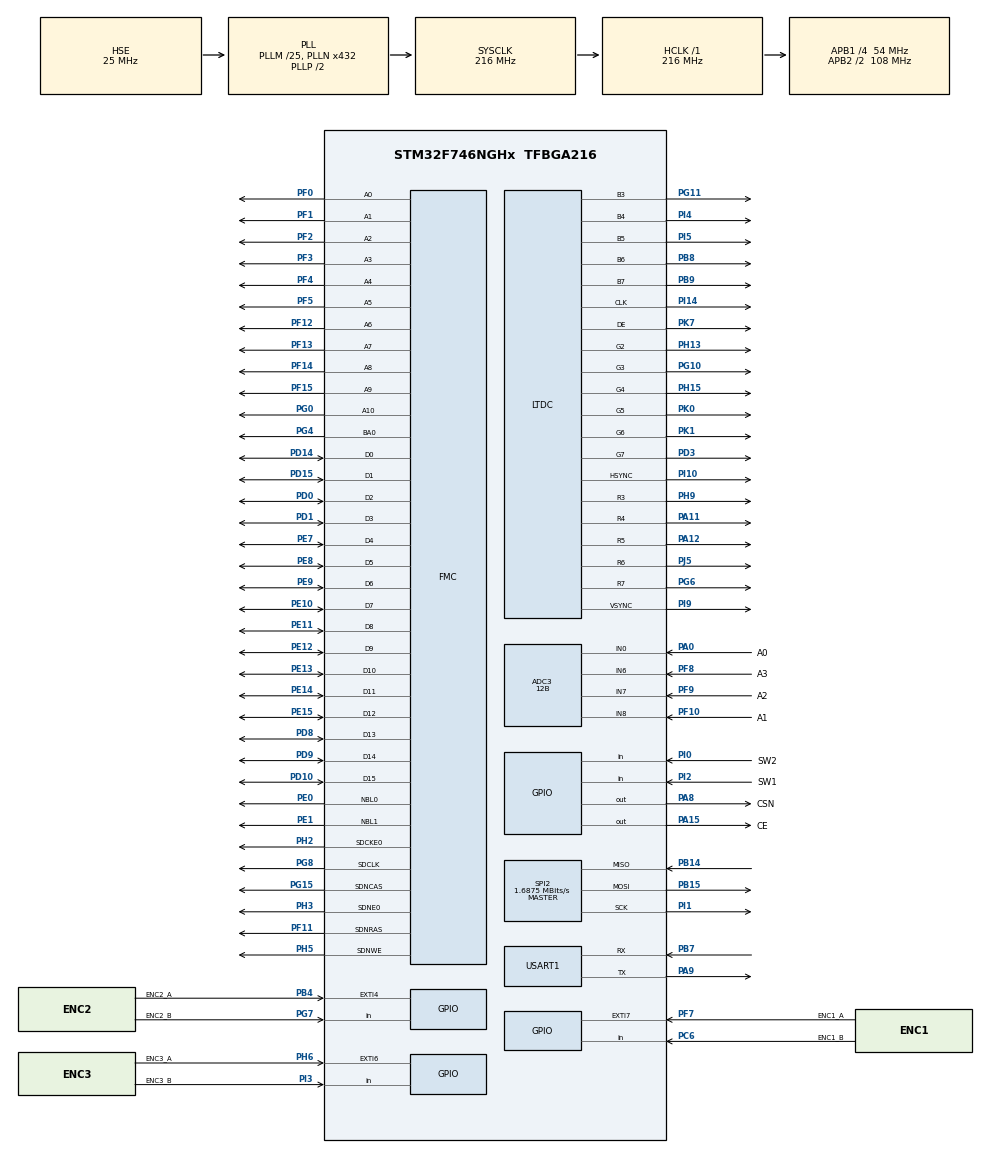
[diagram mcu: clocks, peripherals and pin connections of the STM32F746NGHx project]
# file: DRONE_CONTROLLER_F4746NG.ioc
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ADC3.Channel-0\#ChannelRegularConversion=ADC_CHANNEL_0
ADC3.Channel-1\#ChannelRegularConversion=ADC_CHANNEL_6
ADC3.Channel-2\#ChannelRegularConversion=ADC_CHANNEL_7
ADC3.Channel-3\#ChannelRegularConversion=ADC_CHANNEL_8
ADC3.ClockPrescaler=ADC_CLOCK_SYNC_PCLK_DIV4
ADC3.ContinuousConvMode=DISABLE
ADC3.DMAContinuousRequests=ENABLE
ADC3.EOCSelection=ADC_EOC_SEQ_CONV
ADC3.ExternalTrigConv=ADC_EXTERNALTRIGCONV_T1_TRGO
ADC3.ExternalTrigConvEdge=ADC_EXTERNALTRIGCONVEDGE_RISINGFALLING
ADC3.InjNumberOfConversion=0
ADC3.NbrOfConversion=4
ADC3.NbrOfConversionFlag=1
ADC3.Rank-0\#ChannelRegularConversion=1
ADC3.Rank-1\#ChannelRegularConversion=2
ADC3.Rank-2\#ChannelRegularConversion=3
ADC3.Rank-3\#ChannelRegularConversion=4
ADC3.Resolution=ADC_RESOLUTION_12B
ADC3.SamplingTime-0\#ChannelRegularConversion=ADC_SAMPLETIME_144CYCLES
ADC3.SamplingTime-1\#ChannelRegularConversion=ADC_SAMPLETIME_144CYCLES
ADC3.SamplingTime-2\#ChannelRegularConversion=ADC_SAMPLETIME_144CYCLES
ADC3.SamplingTime-3\#ChannelRegularConversion=ADC_SAMPLETIME_144CYCLES
ADC3.ScanConvMode=ENABLE
CORTEX_M7.ART_ACCLERATOR_ENABLE=1
Dma.ADC3.0.Direction=DMA_PERIPH_TO_MEMORY
Dma.ADC3.0.FIFOMode=DMA_FIFOMODE_DISABLE
Dma.ADC3.0.Instance=DMA2_Stream1
Dma.ADC3.0.MemDataAlignment=DMA_MDATAALIGN_WORD
Dma.ADC3.0.MemInc=DMA_MINC_ENABLE
Dma.ADC3.0.Mode=DMA_CIRCULAR
Dma.ADC3.0.PeriphDataAlignment=DMA_PDATAALIGN_WORD
Dma.ADC3.0.PeriphInc=DMA_PINC_DISABLE
Dma.ADC3.0.Priority=DMA_PRIORITY_HIGH
Dma.Request0=ADC3
FREERTOS.Mutexes01=RxDataMutex,Dynamic,NULL;SwDataMutex,Dynamic,NULL;EncDataMutex,Dynamic,NULL
FREERTOS.Tasks01=DrawUI,0,1024,StartDrawUI,Default,NULL,Dynamic,NULL,NULL;NRFTX,3,512,startNRFTX,Default,NULL,Dynamic,NULL,NULL;ADC,-2,128,StartADC,Default,NULL,Dynamic,NULL,NULL
Mcu.Family=STM32F7
Mcu.Name=STM32F746NGHx
Mcu.Package=TFBGA216
NVIC.ADC_IRQn=true\:5\:0\:false\:false\:true\:true\:true\:true
NVIC.DMA2_Stream1_IRQn=true\:5\:0\:false\:false\:true\:true\:false\:true
NVIC.EXTI4_IRQn=true\:5\:0\:false\:false\:true\:true\:true\:true
NVIC.EXTI9_5_IRQn=true\:5\:0\:false\:false\:true\:true\:true\:true
NVIC.LTDC_IRQn=true\:12\:0\:true\:false\:true\:true\:true\:true
NVIC.PriorityGroup=NVIC_PRIORITYGROUP_4
NVIC.TIM1_UP_TIM10_IRQn=true\:0\:0\:true\:false\:true\:false\:true\:true
NVIC.TIM8_TRG_COM_TIM14_IRQn=true\:0\:0\:false\:false\:true\:false\:false\:true
NVIC.TimeBase=TIM8_TRG_COM_TIM14_IRQn
NVIC.TimeBaseIP=TIM14
PA0/WKUP.GPIO_Label=A0
PA0/WKUP.Signal=ADCx_IN0
PA11.Mode=RGB565
PA11.Signal=LTDC_R4
PA12.Mode=RGB565
PA12.Signal=LTDC_R5
PA13.Mode=Serial_Wire
PA13.Signal=SYS_JTMS-SWDIO
PA14.Mode=Serial_Wire
PA14.Signal=SYS_JTCK-SWCLK
PA15.GPIO_Label=CE
PA15.GPIO_Speed=GPIO_SPEED_FREQ_VERY_HIGH
PA15.Signal=GPIO_Output
PA8.GPIO_Label=CSN
PA8.GPIO_Speed=GPIO_SPEED_FREQ_VERY_HIGH
PA8.Signal=GPIO_Output
PA9.Mode=Asynchronous
PA9.Signal=USART1_TX
PB14.Mode=Full_Duplex_Master
PB14.Signal=SPI2_MISO
PB15.Mode=Full_Duplex_Master
PB15.Signal=SPI2_MOSI
PB4.GPIO_Label=ENC2_A
PB4.GPIO_PuPd=GPIO_PULLUP
PB4.Signal=GPXTI4
PB7.Mode=Asynchronous
PB7.Signal=USART1_RX
PB8.Mode=RGB565
PB8.Signal=LTDC_B6
PB9.Mode=RGB565
PB9.Signal=LTDC_B7
PC6.GPIO_Label=ENC1_B
PC6.GPIO_PuPd=GPIO_PULLUP
PC6.Signal=GPIO_Input
PD0.Signal=FMC_D2_DA2
PD1.Signal=FMC_D3_DA3
PD10.Signal=FMC_D15_DA15
PD14.Signal=FMC_D0_DA0
PD15.Signal=FMC_D1_DA1
PD3.Mode=RGB565
PD3.Signal=LTDC_G7
PD8.Signal=FMC_D13_DA13
PD9.Signal=FMC_D14_DA14
PE0.Signal=FMC_NBL0
PE1.Signal=FMC_NBL1
PE10.Signal=FMC_D7_DA7
PE11.Signal=FMC_D8_DA8
PE12.Signal=FMC_D9_DA9
PE13.Signal=FMC_D10_DA10
PE14.Signal=FMC_D11_DA11
PE15.Signal=FMC_D12_DA12
PE7.Signal=FMC_D4_DA4
PE8.Signal=FMC_D5_DA5
PE9.Signal=FMC_D6_DA6
PF0.Signal=FMC_A0
PF1.Signal=FMC_A1
PF10.GPIO_Label=A1
PF10.Mode=IN8
PF10.Signal=ADC3_IN8
PF11.Signal=FMC_SDNRAS
PF12.Signal=FMC_A6
PF13.Signal=FMC_A7
PF14.Signal=FMC_A8
PF15.Signal=FMC_A9
PF2.Signal=FMC_A2
PF3.Signal=FMC_A3
PF4.Signal=FMC_A4
PF5.Signal=FMC_A5
PF7.GPIO_Label=ENC1_A
PF7.GPIO_PuPd=GPIO_PULLUP
PF7.Signal=GPXTI7
PF8.GPIO_Label=A3
PF8.Mode=IN6
PF8.Signal=ADC3_IN6
PF9.GPIO_Label=A2
PF9.Mode=IN7
PF9.Signal=ADC3_IN7
PG0.Signal=FMC_A10
PG10.Mode=RGB565
PG10.Signal=LTDC_G3
PG11.Mode=RGB565
PG11.Signal=LTDC_B3
PG15.Signal=FMC_SDNCAS
PG4.Signal=FMC_A14_BA0
PG6.Mode=RGB565
PG6.Signal=LTDC_R7
PG7.GPIO_Label=ENC2_B
PG7.GPIO_PuPd=GPIO_PULLUP
PG7.Signal=GPIO_Input
PG8.Signal=FMC_SDCLK
PH0/OSC_IN.Mode=HSE-External-Oscillator
PH0/OSC_IN.Signal=RCC_OSC_IN
PH1/OSC_OUT.Mode=HSE-External-Oscillator
PH1/OSC_OUT.Signal=RCC_OSC_OUT
PH13.Mode=RGB565
PH13.Signal=LTDC_G2
PH15.Mode=RGB565
PH15.Signal=LTDC_G4
PH2.Mode=SdramChipSelect1_1
PH2.Signal=FMC_SDCKE0
PH3.Mode=SdramChipSelect1_1
PH3.Signal=FMC_SDNE0
PH5.Signal=FMC_SDNWE
PH6.GPIO_Label=ENC3_A
PH6.GPIO_PuPd=GPIO_PULLUP
PH6.Signal=GPXTI6
PH9.Mode=RGB565
PH9.Signal=LTDC_R3
PI0.GPIO_Label=SW2
PI0.GPIO_PuPd=GPIO_PULLUP
PI0.Signal=GPIO_Input
PI1.Mode=Full_Duplex_Master
PI1.Signal=SPI2_SCK
PI10.Mode=RGB565
PI10.Signal=LTDC_HSYNC
PI14.Mode=RGB565
PI14.Signal=LTDC_CLK
PI2.GPIO_Label=SW1
PI2.GPIO_PuPd=GPIO_PULLUP
PI2.Signal=GPIO_Input
PI3.GPIO_Label=ENC3_B
PI3.GPIO_PuPd=GPIO_PULLUP
PI3.Signal=GPIO_Input
PI4.Mode=RGB565
PI4.Signal=LTDC_B4
PI5.Mode=RGB565
PI5.Signal=LTDC_B5
PI9.Mode=RGB565
PI9.Signal=LTDC_VSYNC
PJ5.Mode=RGB565
PJ5.Signal=LTDC_R6
PK0.Mode=RGB565
PK0.Signal=LTDC_G5
PK1.Mode=RGB565
PK1.Signal=LTDC_G6
PK7.Mode=RGB565
PK7.Signal=LTDC_DE
ProjectManager.HeapSize=0x200
ProjectManager.StackSize=0x400
ProjectManager.TargetToolchain=STM32CubeIDE
RCC.AHBFreq_Value=216000000
RCC.APB1CLKDivider=RCC_HCLK_DIV4
RCC.APB1Freq_Value=54000000
RCC.APB1TimFreq_Value=108000000
RCC.APB2CLKDivider=RCC_HCLK_DIV2
RCC.APB2Freq_Value=108000000
RCC.APB2TimFreq_Value=216000000
RCC.CortexFreq_Value=216000000
RCC.HCLKFreq_Value=216000000
RCC.HSE_VALUE=25000000
RCC.HSI_VALUE=16000000
RCC.LSE_VALUE=32768
RCC.PLL48CLockSelection=RCC_CLK48SOURCE_PLLSAIP
RCC.PLLI2SN=100
RCC.PLLM=25
RCC.PLLN=432
RCC.PLLQ=9
RCC.PLLSAIN=384
RCC.PLLSAIP=RCC_PLLSAIP_DIV8
RCC.PLLSAIR=5
RCC.PLLSAIRDiv=RCC_PLLSAIDIVR_8
RCC.PLLSourceVirtual=RCC_PLLSOURCE_HSE
RCC.SDMMCClockSelection=RCC_SDMMC1CLKSOURCE_CLK48
RCC.SYSCLKFreq_VALUE=216000000
RCC.SYSCLKSource=RCC_SYSCLKSOURCE_PLLCLK
RCC.USBFreq_Value=48000000
RCC.VCOOutputFreq_Value=432000000
SH.ADCx_IN0.0=ADC3_IN0,IN0
SH.FMC_A0.0=FMC_A0,11b-sda1
SH.FMC_A1.0=FMC_A1,11b-sda1
SH.FMC_A10.0=FMC_A10,11b-sda1
SH.FMC_A14_BA0.0=FMC_BA0,TwoSdramBanks1
SH.FMC_A2.0=FMC_A2,11b-sda1
SH.FMC_A3.0=FMC_A3,11b-sda1
SH.FMC_A4.0=FMC_A4,11b-sda1
SH.FMC_A5.0=FMC_A5,11b-sda1
SH.FMC_A6.0=FMC_A6,11b-sda1
SH.FMC_A7.0=FMC_A7,11b-sda1
SH.FMC_A8.0=FMC_A8,11b-sda1
SH.FMC_A9.0=FMC_A9,11b-sda1
SH.FMC_D0_DA0.0=FMC_D0,sd-16b-d1
SH.FMC_D10_DA10.0=FMC_D10,sd-16b-d1
SH.FMC_D11_DA11.0=FMC_D11,sd-16b-d1
SH.FMC_D12_DA12.0=FMC_D12,sd-16b-d1
SH.FMC_D13_DA13.0=FMC_D13,sd-16b-d1
SH.FMC_D14_DA14.0=FMC_D14,sd-16b-d1
SH.FMC_D15_DA15.0=FMC_D15,sd-16b-d1
SH.FMC_D1_DA1.0=FMC_D1,sd-16b-d1
SH.FMC_D2_DA2.0=FMC_D2,sd-16b-d1
SH.FMC_D3_DA3.0=FMC_D3,sd-16b-d1
SH.FMC_D4_DA4.0=FMC_D4,sd-16b-d1
SH.FMC_D5_DA5.0=FMC_D5,sd-16b-d1
SH.FMC_D6_DA6.0=FMC_D6,sd-16b-d1
SH.FMC_D7_DA7.0=FMC_D7,sd-16b-d1
SH.FMC_D8_DA8.0=FMC_D8,sd-16b-d1
SH.FMC_D9_DA9.0=FMC_D9,sd-16b-d1
SH.FMC_NBL0.0=FMC_NBL0,Sd2ByteEnable1
SH.FMC_NBL1.0=FMC_NBL1,Sd2ByteEnable1
SH.FMC_SDCLK.0=FMC_SDCLK,11b-sda1
SH.FMC_SDNCAS.0=FMC_SDNCAS,11b-sda1
SH.FMC_SDNRAS.0=FMC_SDNRAS,11b-sda1
SH.FMC_SDNWE.0=FMC_SDNWE,11b-sda1
SPI2.BaudRatePrescaler=SPI_BAUDRATEPRESCALER_32
SPI2.CalculateBaudRate=1.6875 MBits/s
SPI2.DataSize=SPI_DATASIZE_8BIT
SPI2.Direction=SPI_DIRECTION_2LINES
SPI2.Mode=SPI_MODE_MASTER
SPI2.VirtualType=VM_MASTER
TIM1.Period=216-1
TIM1.Prescaler=10000-1
TIM1.TIM_MasterOutputTrigger=TIM_TRGO_UPDATE
TIM1.TIM_MasterOutputTrigger2=TIM_TRGO2_UPDATE
USART1.VirtualMode-Asynchronous=VM_ASYNC
VP_CRC_VS_CRC.Mode=CRC_Activate
VP_DMA2D_VS_DMA2D.Mode=DMA2D_Activate
VP_FREERTOS_VS_CMSIS_V1.Mode=CMSIS_V1
VP_SYS_VS_tim14.Mode=TIM14
VP_TIM1_VS_ClockSourceINT.Mode=Internal
board=STM32F746G-DISCO

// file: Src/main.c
/* USER CODE BEGIN Header */
/**
 ******************************************************************************
 * @file           : main.c
 * @brief          : Main program body
 ******************************************************************************
 * @attention
 *
 * <h2><center>&copy; Copyright (c) 2019 STMicroelectronics.
 * All rights reserved.</center></h2>
 *
 * This software component is licensed by ST under Ultimate Liberty license
 * SLA0044, the "License"; You may not use this file except in compliance with
 * the License. You may obtain a copy of the License at:
 *                             www.st.com/SLA0044
 *
 ******************************************************************************
 */
/* USER CODE END Header */

#include "main.h"
#include "cmsis_os.h"
#include "adc.h"
#include "crc.h"
#include "dma.h"
#include "dma2d.h"
#include "ltdc.h"
#include "spi.h"
#include "tim.h"
#include "usart.h"
#include "gpio.h"
#include "fmc.h"

/* USER CODE BEGIN Includes */

#include <string.h>
#include <stdio.h>
#include <math.h>
/* USER CODE END Includes */

/* USER CODE BEGIN PV */

uint32_t A0, A1, A2, A3;

/* USER CODE END PV */

void SystemClock_Config(void);
void MX_FREERTOS_Init(void);
/* USER CODE BEGIN PFP */

float map(int x, int in_min, int in_max, int out_min, int out_max);

void sendPayload();
/* USER CODE END PFP */

/* USER CODE BEGIN 0 */

int counter = 0;

//Touch screen variables
TS_StateTypeDef ts;

char xTouchStr[10];

/* USER CODE END 0 */

int main(void)
{
  /* USER CODE BEGIN 1 */
	/* Enable the CPU Cache */
	/* Enable I-Cache */
	SCB_EnableICache();
	/* Enable D-Cache */
	SCB_EnableDCache();
  /* USER CODE END 1 */

  /* MCU Configuration--------------------------------------------------------*/

  /* Reset of all peripherals, Initializes the Flash interface and the Systick. */
  HAL_Init();

  /* Configure the system clock */
  SystemClock_Config();

  /* Initialize all configured peripherals */
  MX_GPIO_Init();
  MX_DMA_Init();
  MX_SPI2_Init();
  MX_USART1_UART_Init();
  MX_ADC3_Init();
  MX_CRC_Init();
  MX_DMA2D_Init();
  MX_FMC_Init();
  MX_LTDC_Init();
  MX_TIM1_Init();
  /* USER CODE BEGIN 2 */

	//NRF24 Module Initialisation functions

  /* USER CODE END 2 */

  /* Call init function for freertos objects (in freertos.c) */
  MX_FREERTOS_Init();

  /* Start scheduler */
  osKernelStart();

  /* We should never get here as control is now taken by the scheduler */

  /* Infinite loop */
	while (1)
	{

	}
}

void SystemClock_Config(void)
{
  RCC_OscInitTypeDef RCC_OscInitStruct = {0};
  RCC_ClkInitTypeDef RCC_ClkInitStruct = {0};
  RCC_PeriphCLKInitTypeDef PeriphClkInitStruct = {0};

  /** Configure the main internal regulator output voltage
  */
  __HAL_RCC_PWR_CLK_ENABLE();
  __HAL_PWR_VOLTAGESCALING_CONFIG(PWR_REGULATOR_VOLTAGE_SCALE1);
  /** Initializes the CPU, AHB and APB busses clocks
  */
  RCC_OscInitStruct.OscillatorType = RCC_OSCILLATORTYPE_HSE;
  RCC_OscInitStruct.HSEState = RCC_HSE_ON;
  RCC_OscInitStruct.PLL.PLLState = RCC_PLL_ON;
  RCC_OscInitStruct.PLL.PLLSource = RCC_PLLSOURCE_HSE;
  RCC_OscInitStruct.PLL.PLLM = 25;
  RCC_OscInitStruct.PLL.PLLN = 432;
  RCC_OscInitStruct.PLL.PLLP = RCC_PLLP_DIV2;
  RCC_OscInitStruct.PLL.PLLQ = 9;
  if (HAL_RCC_OscConfig(&RCC_OscInitStruct) != HAL_OK)
  {
    Error_Handler();
  }
  /** Activate the Over-Drive mode
  */
  if (HAL_PWREx_EnableOverDrive() != HAL_OK)
  {
    Error_Handler();
  }
  /** Initializes the CPU, AHB and APB busses clocks
  */
  RCC_ClkInitStruct.ClockType = RCC_CLOCKTYPE_HCLK|RCC_CLOCKTYPE_SYSCLK
                              |RCC_CLOCKTYPE_PCLK1|RCC_CLOCKTYPE_PCLK2;
  RCC_ClkInitStruct.SYSCLKSource = RCC_SYSCLKSOURCE_PLLCLK;
  RCC_ClkInitStruct.AHBCLKDivider = RCC_SYSCLK_DIV1;
  RCC_ClkInitStruct.APB1CLKDivider = RCC_HCLK_DIV4;
  RCC_ClkInitStruct.APB2CLKDivider = RCC_HCLK_DIV2;

  if (HAL_RCC_ClockConfig(&RCC_ClkInitStruct, FLASH_LATENCY_7) != HAL_OK)
  {
    Error_Handler();
  }
  PeriphClkInitStruct.PeriphClockSelection = RCC_PERIPHCLK_LTDC|RCC_PERIPHCLK_USART1;
  PeriphClkInitStruct.PLLSAI.PLLSAIN = 384;
  PeriphClkInitStruct.PLLSAI.PLLSAIR = 5;
  PeriphClkInitStruct.PLLSAI.PLLSAIQ = 2;
  PeriphClkInitStruct.PLLSAI.PLLSAIP = RCC_PLLSAIP_DIV8;
  PeriphClkInitStruct.PLLSAIDivQ = 1;
  PeriphClkInitStruct.PLLSAIDivR = RCC_PLLSAIDIVR_8;
  PeriphClkInitStruct.Usart1ClockSelection = RCC_USART1CLKSOURCE_PCLK2;
  if (HAL_RCCEx_PeriphCLKConfig(&PeriphClkInitStruct) != HAL_OK)
  {
    Error_Handler();
  }
}

/* USER CODE BEGIN 4 */

void HAL_ADC_ConvCpltCallback(ADC_HandleTypeDef* hadc)
{

}

/* USER CODE END 4 */

void HAL_TIM_PeriodElapsedCallback(TIM_HandleTypeDef *htim)
{
  if (htim->Instance == TIM14) {
    HAL_IncTick();
  }
}

void Error_Handler(void)
{
}

/************************ (C) COPYRIGHT STMicroelectronics *****END OF FILE****/

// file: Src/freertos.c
/* USER CODE BEGIN Header */
/**
 ******************************************************************************
 * File Name          : freertos.c
 * Description        : Code for freertos applications
 ******************************************************************************
 * @attention
 *
 * <h2><center>&copy; Copyright (c) 2019 STMicroelectronics.
 * All rights reserved.</center></h2>
 *
 * This software component is licensed by ST under Ultimate Liberty license
 * SLA0044, the "License"; You may not use this file except in compliance with
 * the License. You may obtain a copy of the License at:
 *                             www.st.com/SLA0044
 *
 ******************************************************************************
 */
/* USER CODE END Header */

#include "FreeRTOS.h"
#include "task.h"
#include "main.h"
#include "cmsis_os.h"

/* USER CODE BEGIN Includes */
#include "../GUI/GUI.h"
#include "../Drivers/NRF24_Top.h"
#include "adc.h"
#include "tim.h"

/* USER CODE END Includes */

/* USER CODE BEGIN Variables */
uint32_t adcArray[4];

bool enc1_A;
bool enc1_B;

/* USER CODE END Variables */
osThreadId DrawUIHandle;
osThreadId NRFTXHandle;
osThreadId ADCHandle;
osMutexId RxDataMutexHandle;
osMutexId SwDataMutexHandle;
osMutexId EncDataMutexHandle;

/* USER CODE BEGIN FunctionPrototypes */
int8_t read_rotary_1();
int8_t read_rotary_2();
int8_t read_rotary_3();

static uint8_t prevNextCode_1 = 0;
static uint16_t store_1 = 0;

static uint8_t prevNextCode_2 = 0;
static uint16_t store_2 = 0;

static uint8_t prevNextCode_3 = 0;
static uint16_t store_3 = 0;

//Which axis is currently being tuned
// 0 = Roll, 3 = Pitch, 6 = Yaw
uint8_t tune_axis = 0;
float enc_pid[6] = { 0.00, 0.000, 0.000, 0.00, 0.000, 0.000 };

/* USER CODE END FunctionPrototypes */

void StartDrawUI(void const * argument);
void startNRFTX(void const * argument);
void StartADC(void const * argument);

void MX_FREERTOS_Init(void); /* (MISRA C 2004 rule 8.1) */

void MX_FREERTOS_Init(void) {

  /* Create the mutex(es) */
  /* definition and creation of RxDataMutex */
  osMutexDef(RxDataMutex);
  RxDataMutexHandle = osMutexCreate(osMutex(RxDataMutex));

  /* definition and creation of SwDataMutex */
  osMutexDef(SwDataMutex);
  SwDataMutexHandle = osMutexCreate(osMutex(SwDataMutex));

  /* definition and creation of EncDataMutex */
  osMutexDef(EncDataMutex);
  EncDataMutexHandle = osMutexCreate(osMutex(EncDataMutex));

  /* Create the thread(s) */
  /* definition and creation of DrawUI */
  osThreadDef(DrawUI, StartDrawUI, osPriorityNormal, 0, 1024);
  DrawUIHandle = osThreadCreate(osThread(DrawUI), NULL);

  /* definition and creation of NRFTX */
  osThreadDef(NRFTX, startNRFTX, osPriorityRealtime, 0, 512);
  NRFTXHandle = osThreadCreate(osThread(NRFTX), NULL);

  /* definition and creation of ADC */
  osThreadDef(ADC, StartADC, osPriorityLow, 0, 128);
  ADCHandle = osThreadCreate(osThread(ADC), NULL);

}

void StartDrawUI(void const * argument)
{

  /* USER CODE BEGIN StartDrawUI */
	xSemaphoreTake(RxDataMutexHandle, portMAX_DELAY);
	initLCD(GPS);
	xSemaphoreGive(RxDataMutexHandle);

	/* Infinite loop */
	for (;;) {
		xSemaphoreTake(RxDataMutexHandle, portMAX_DELAY);
		xSemaphoreTake(SwDataMutexHandle, portMAX_DELAY);
		xSemaphoreTake(EncDataMutexHandle, portMAX_DELAY);
		drawUI(GPS, IMU, Misc, enc_pid, &tune_axis);
		xSemaphoreGive(RxDataMutexHandle);
		xSemaphoreGive(SwDataMutexHandle);
		xSemaphoreGive(EncDataMutexHandle);
		osDelay(2);
	}
  /* USER CODE END StartDrawUI */
}

void startNRFTX(void const * argument)
{
  /* USER CODE BEGIN startNRFTX */

	Misc.kill = 0;
	Misc.airmode = 0;
	xSemaphoreTake(RxDataMutexHandle, portMAX_DELAY);
	NRF24_init(GPS);
	xSemaphoreGive(RxDataMutexHandle);
	/* Infinite loop */
	for (;;) {

		xSemaphoreTake(SwDataMutexHandle, portMAX_DELAY);
		xSemaphoreTake(EncDataMutexHandle, portMAX_DELAY);
		packData(adcArray, Misc.airmode, Misc.kill, enc_pid);
		xSemaphoreGive(SwDataMutexHandle);
		xSemaphoreGive(EncDataMutexHandle);

		xSemaphoreTake(RxDataMutexHandle, portMAX_DELAY);
		Misc.connection = sendPayload();
		xSemaphoreGive(RxDataMutexHandle);

		osDelay(5);
	}
  /* USER CODE END startNRFTX */
}

void StartADC(void const * argument)
{
  /* USER CODE BEGIN StartADC */

	//	//Init ADC for DMA
	if (HAL_ADC_Start(&hadc3) == HAL_OK) {
		HAL_ADC_Start_DMA(&hadc3, (uint32_t *) adcArray, 4);
		HAL_TIM_Base_Start(&htim1);

	}

	/* Infinite loop */
	for (;;) {

		xSemaphoreTake(SwDataMutexHandle, portMAX_DELAY);
		if (HAL_GPIO_ReadPin(GPIOI, GPIO_PIN_2) == GPIO_PIN_SET) {
			Misc.airmode = 1;
		} else {
			Misc.airmode = 0;
		}

		//SW2 - Kill switch
		if (HAL_GPIO_ReadPin(GPIOI, SW2_Pin) == GPIO_PIN_RESET) {
			Misc.kill = 1;
		} else {
			Misc.kill = 0;
		}
		xSemaphoreGive(SwDataMutexHandle);
		osDelay(50);
	}
  /* USER CODE END StartADC */
}

/* USER CODE BEGIN Application */

//GPIO interrupt callback
void HAL_GPIO_EXTI_Callback(uint16_t GPIO_Pin) {

	//Encoder 1 Pin A interrupt
	if (GPIO_Pin == GPIO_PIN_7) {
		if (read_rotary_1()) {

			if (prevNextCode_1 == 0x0b) {
				if (enc_pid[tune_axis + 2] > 0) {
					enc_pid[tune_axis + 2] -= 0.1;
				}
			}
			if (prevNextCode_1 == 0x07) {
				enc_pid[tune_axis + 2] += 0.1;
			}
		}
	}
	//Encoder 2 Pin A interrupt
	if (GPIO_Pin == GPIO_PIN_4) {
		if (read_rotary_2()) {

			if (prevNextCode_2 == 0x0b) {
				if (enc_pid[tune_axis + 1] > 0) {
					enc_pid[tune_axis + 1] -= 0.1;
				}
			}

			if (prevNextCode_2 == 0x07) {
				enc_pid[tune_axis + 1] += 0.1;
			}
		}
	}
	//Encoder 3 Pin A interrupt
	if (GPIO_Pin == GPIO_PIN_6) {

		if (read_rotary_3()) {

			if (prevNextCode_3 == 0x0b) {
				if (enc_pid[tune_axis + 0] > 0) {
					enc_pid[tune_axis + 0] -= 0.5;
				}
			}
			if (prevNextCode_3 == 0x07) {
				enc_pid[tune_axis + 0] += 0.5;
			}
		}
	}

}

// A vald CW or  CCW move returns 1, invalid returns 0.
int8_t read_rotary_1() {
	static int8_t rot_enc_table[] = { 0, 1, 1, 0, 1, 0, 0, 1, 1, 0, 0, 1, 0, 1,
			1, 0 };

	prevNextCode_1 <<= 2;

	if (HAL_GPIO_ReadPin(GPIOF, ENC1_A_Pin) == GPIO_PIN_SET)
		prevNextCode_1 |= 0x02;
	if (HAL_GPIO_ReadPin(GPIOC, ENC1_B_Pin) == GPIO_PIN_SET)
		prevNextCode_1 |= 0x01;
	prevNextCode_1 &= 0x0f;

	// If valid then store_1 as 16 bit data.
	if (rot_enc_table[prevNextCode_1]) {
		store_1 <<= 4;
		store_1 |= prevNextCode_1;

		if ((store_1 & 0xff) == 0x2b)
			return -1;
		if ((store_1 & 0xff) == 0x17)
			return 1;
	}
	return 0;
}

// A vald CW or  CCW move returns 1, invalid returns 0.
int8_t read_rotary_2() {
	static int8_t rot_enc_table[] = { 0, 1, 1, 0, 1, 0, 0, 1, 1, 0, 0, 1, 0, 1,
			1, 0 };

	prevNextCode_2 <<= 2;

	if (HAL_GPIO_ReadPin(GPIOB, ENC2_A_Pin) == GPIO_PIN_SET)
		prevNextCode_2 |= 0x02;
	if (HAL_GPIO_ReadPin(GPIOG, ENC2_B_Pin) == GPIO_PIN_SET)
		prevNextCode_2 |= 0x01;
	prevNextCode_2 &= 0x0f;

	// If valid then store_2 as 16 bit data.
	if (rot_enc_table[prevNextCode_2]) {
		store_2 <<= 4;
		store_2 |= prevNextCode_2;

		if ((store_2 & 0xff) == 0x2b)
			return -1;
		if ((store_2 & 0xff) == 0x17)
			return 1;
	}
	return 0;
}

// A vald CW or  CCW move returns 1, invalid returns 0.
int8_t read_rotary_3() {
	static int8_t rot_enc_table[] = { 0, 1, 1, 0, 1, 0, 0, 1, 1, 0, 0, 1, 0, 1,
			1, 0 };

	prevNextCode_3 <<= 2;

	if (HAL_GPIO_ReadPin(GPIOH, ENC3_A_Pin) == GPIO_PIN_SET)
		prevNextCode_3 |= 0x02;
	if (HAL_GPIO_ReadPin(GPIOI, ENC3_B_Pin) == GPIO_PIN_SET)
		prevNextCode_3 |= 0x01;
	prevNextCode_3 &= 0x0f;

	// If valid then store_1 as 16 bit data.
	if (rot_enc_table[prevNextCode_3]) {
		store_3 <<= 4;
		store_3 |= prevNextCode_3;

		if ((store_3 & 0xff) == 0x2b)
			return -1;
		if ((store_3 & 0xff) == 0x17)
			return 1;
	}
	return 0;
}

/* USER CODE END Application */

/************************ (C) COPYRIGHT STMicroelectronics *****END OF FILE****/
